# XMC4300 register map
Vendor: Infineon; File version: 0.5.1 (Superset device XMC4800)
CPU: CM4 r2p0, little endian, MPU, FPU, 6 interrupt priority bits
Registers are 32-bit, read-write, reset 0x0 unless marked. A register's access mark holds for its fields unless they carry their own. Offsets are from the block's base; [hi:lo] are bit positions; 'fields as' and 'values as' point back to an identical list.

## USB0_EP1 — Universal Serial Bus
Base 0x50040920
Same registers: USB0_EP2 0x50040940, USB0_EP3 0x50040960, USB0_EP4 0x50040980, USB0_EP5 0x500409A0, USB0_EP6 0x500409C0
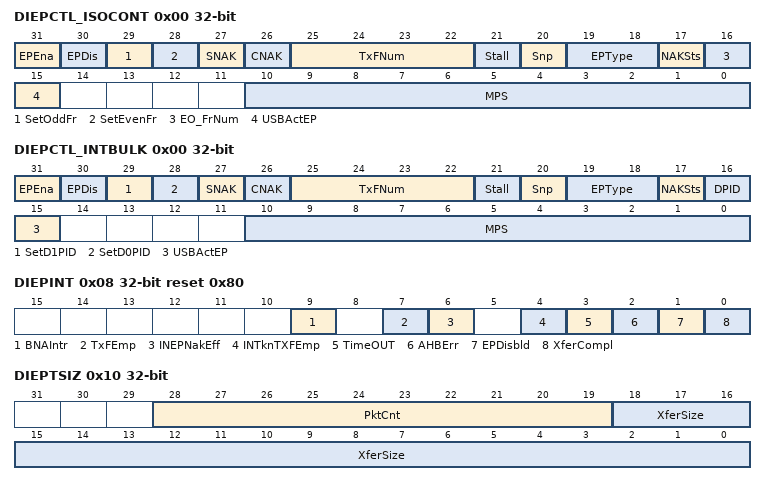
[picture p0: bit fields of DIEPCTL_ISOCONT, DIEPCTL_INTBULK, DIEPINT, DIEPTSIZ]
0x00 DIEPCTL_ISOCONT access per field — Device Endpoint Control Register [ISOCONT]
  [31] EPEna rw — Endpoint Enable
  [30] EPDis rw — Endpoint Disable
  [29] SetOddFr wo — Set Odd frame
  [28] SetEvenFr wo — In non-Scatter/Gather DMA mode: Set Even frame
  [27] SNAK wo — Set NAK
  [26] CNAK wo — Clear NAK
  [25:22] TxFNum rw — TxFIFO Number
  [21] Stall rw — STALL Handshake
  [20] Snp rw — Snoop Mode
  [19:18] EPType rw — Endpoint Type
    0=Control; 1=Isochronous; 2=Bulk; 3=Interrupt
  [17] NAKSts ro — NAK Status
    0=The core is transmitting non-NAK handshakes based on the FIFO status; 1=The core is transmitting NAK handshakes on this endpoint
  [16] EO_FrNum ro — Even/Odd Frame
    0=Even frame; 1=Odd rame
  [15] USBActEP rw — USB Active Endpoint
  [10:0] MPS rw — Maximum Packet Size
0x00 DIEPCTL_INTBULK access per field (alternate view of DIEPCTL_ISOCONT) — Device Endpoint Control Register [INTBULK]
  [31] EPEna rw — Endpoint Enable
  [30] EPDis rw — Endpoint Disable
  [29] SetD1PID wo — 29 Set DATA1 PID
  [28] SetD0PID wo — Set DATA0 PID
  [27] SNAK wo — Set NAK
  [26] CNAK wo — Clear NAK
  [25:22] TxFNum rw — TxFIFO Number
  [21] Stall rw — STALL Handshake
  [20] Snp rw — Snoop Mode
  [19:18] EPType rw — Endpoint Type
    0=Control; 1=Isochronous; 2=Bulk; 3=Interrupt
  [17] NAKSts ro — NAK Status
    values as DIEPCTL_ISOCONT.NAKSts
  [16] DPID ro — Endpoint Data PID
    0=DATA0; 1=DATA1
  [15] USBActEP rw — USB Active Endpoint
  [10:0] MPS rw — Maximum Packet Size
0x08 DIEPINT access per field reset 0x80 — Device Endpoint Interrupt Register
  [9] BNAIntr rw — BNA (Buffer Not Available) Interrupt
  [7] TxFEmp ro — Transmit FIFO Empty
  [6] INEPNakEff rw — IN Endpoint NAK Effective
  [4] INTknTXFEmp rw — IN Token Received When TxFIFO is Empty
  [3] TimeOUT rw — Timeout Condition
  [2] AHBErr rw — AHB Error
  [1] EPDisbld rw — Endpoint Disabled Interrupt
  [0] XferCompl rw — Transfer Completed Interrupt
0x10 DIEPTSIZ — Device Endpoint Transfer Size Register
  [28:19] PktCnt — Packet Count
  [18:0] XferSize — Transfer Size
0x14 DIEPDMA reset not defined read-has-side-effects — Device Endpoint DMA Address Register
  [31:0] DMAAddr — DMA Address
0x18 DTXFSTS ro — Device IN Endpoint Transmit FIFO Status Register
  [15:0] INEPTxFSpcAvail — IN Endpoint TxFIFO Space Avail
    0=Endpoint TxFIFO is full; 1=1 word available; 2=2 words available
0x1C DIEPDMAB ro reset not defined — Device Endpoint DMA Buffer Address Register
  [31:0] DMABufferAddr — DMA Buffer Address
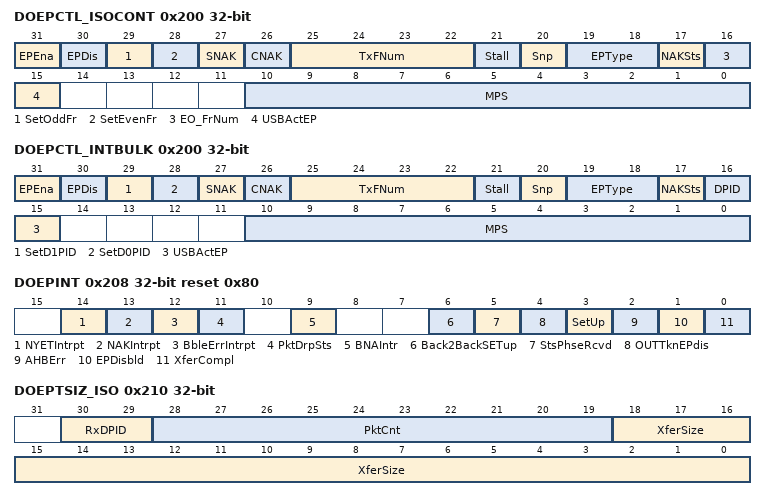
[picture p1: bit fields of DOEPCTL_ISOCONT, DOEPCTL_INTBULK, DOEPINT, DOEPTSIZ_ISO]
0x200 DOEPCTL_ISOCONT access per field — Device Endpoint Control Register [ISOCONT]
  fields as DIEPCTL_ISOCONT
0x200 DOEPCTL_INTBULK access per field (alternate view of DOEPCTL_ISOCONT) — Device Endpoint Control Register [INTBULK]
  fields as DIEPCTL_INTBULK
0x208 DOEPINT reset 0x80 — Device Endpoint Interrupt Register
  [14] NYETIntrpt — NYET interrupt
  [13] NAKIntrpt — NAK interrupt
  [12] BbleErrIntrpt — BbleErr (Babble Error) interrupt
  [11] PktDrpSts — Packet Dropped Status
  [9] BNAIntr — BNA (Buffer Not Available) Interrupt
  [6] Back2BackSETup — Back-to-Back SETUP Packets Received
  [5] StsPhseRcvd — Status Phase Received For Control Write
  [4] OUTTknEPdis — OUT Token Received When Endpoint Disabled
  [3] SetUp — SETUP Phase Done
  [2] AHBErr — AHB Error
  [1] EPDisbld — Endpoint Disabled Interrupt
  [0] XferCompl — Transfer Completed Interrupt
0x210 DOEPTSIZ_ISO access per field — Device Endpoint Transfer Size Register [ISO]
  [30:29] RxDPID ro — Received Data PID
    0=DATA0; 1=DATA2; 2=DATA1; 3=MDATA
  [28:19] PktCnt rw — Packet Count
  [18:0] XferSize rw — Transfer Size
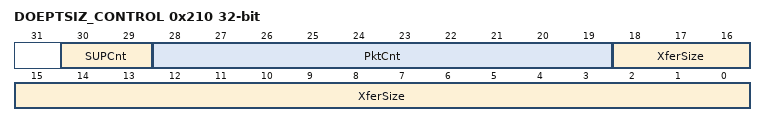
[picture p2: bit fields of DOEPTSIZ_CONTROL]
0x210 DOEPTSIZ_CONTROL (alternate view of DOEPTSIZ_ISO) — Device Endpoint Transfer Size Register [CONT]
  [30:29] SUPCnt — SETUP Packet Count: 0b00=1 packet, 0b00=2 packets, 0b00=3 packets,
  [28:19] PktCnt — Packet Count
  [18:0] XferSize — Transfer Size
0x214 DOEPDMA reset not defined read-has-side-effects — Device Endpoint DMA Address Register
  [31:0] DMAAddr — DMA Address
0x21C DOEPDMAB ro reset not defined — Device Endpoint DMA Buffer Address Register
  [31:0] DMABufferAddr — DMA Buffer Address
